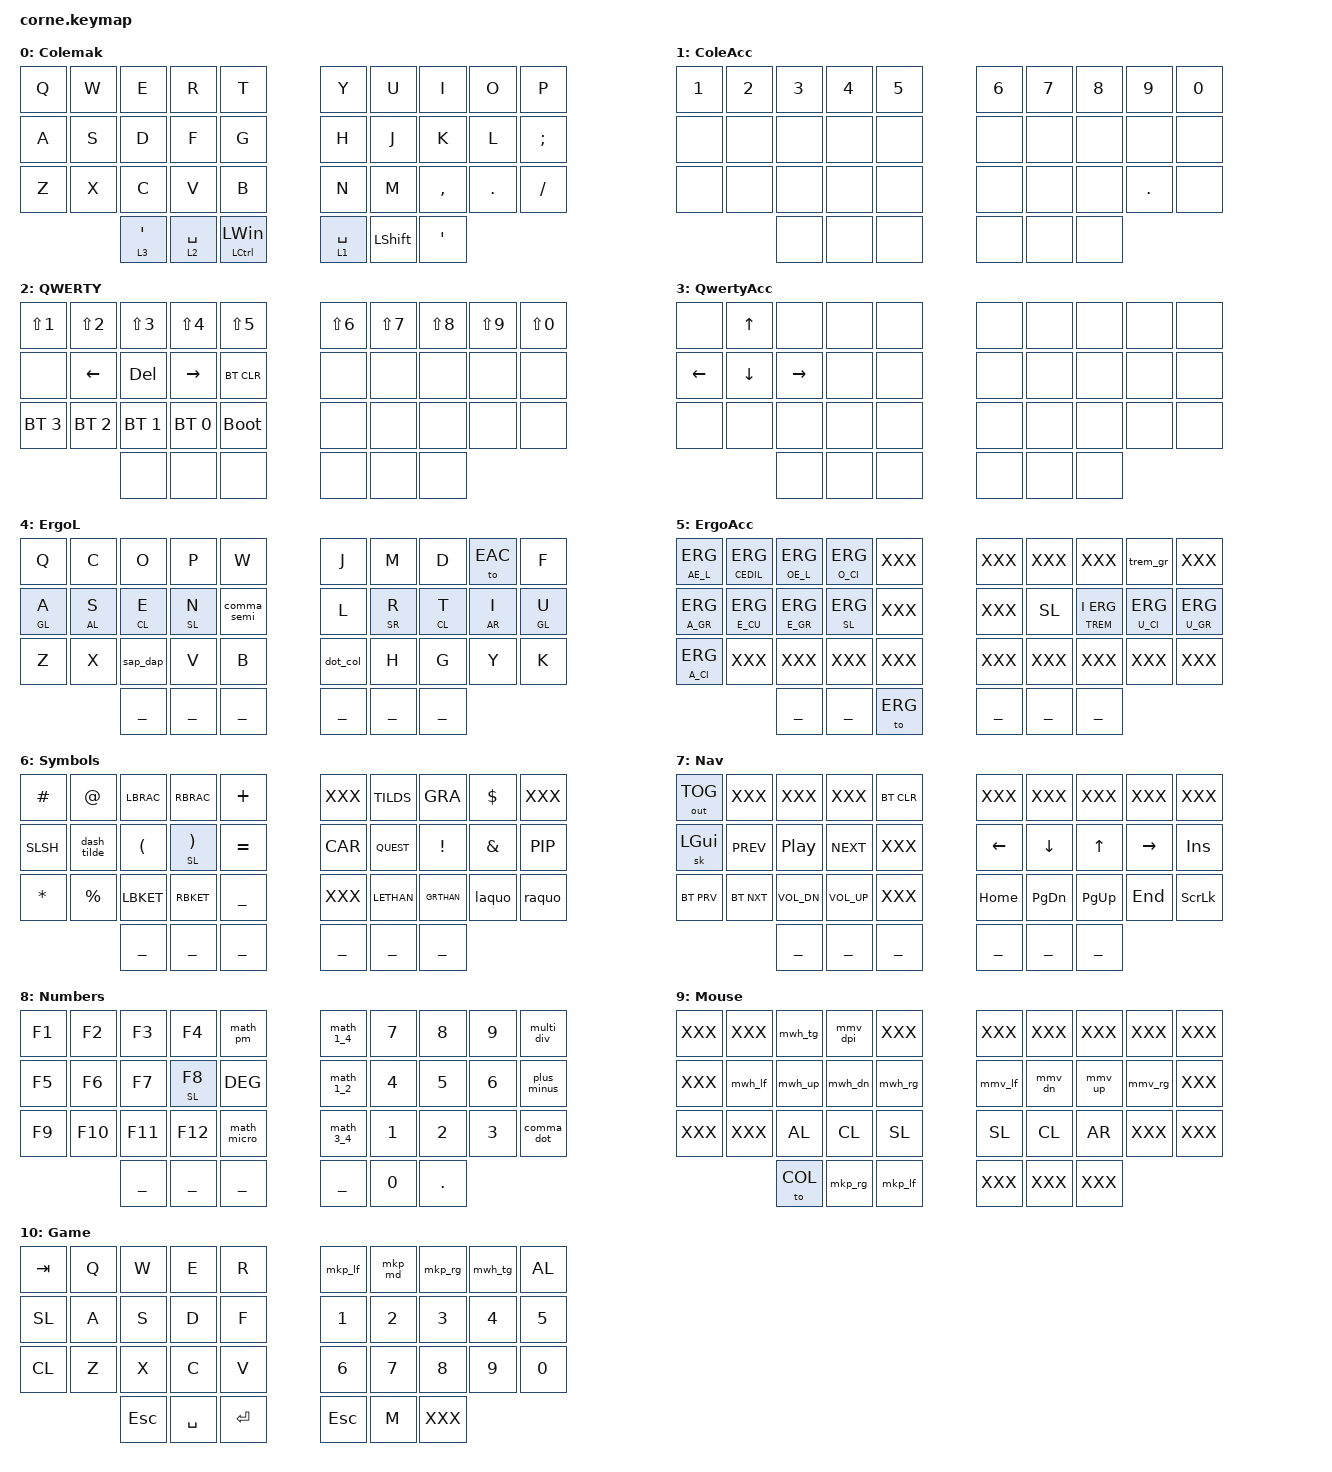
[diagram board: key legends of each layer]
#include <behaviors.dtsi>
#include <behaviors/mouse_keys.dtsi>
#include <dt-bindings/zmk/keys.h>
#include <dt-bindings/zmk/bt.h>
#include <dt-bindings/zmk/outputs.h>
#include <dt-bindings/zmk/mouse.h>

#include "constants.h"
#define HOST_OS LINUX // Needed for unicode international_chars

#include "zmk-helpers/helper.h"
#include "zmk-helpers/key-labels/36.h"
#include "../chars/french.dtsi"
#include "../chars/math.dtsi"
#include "../chars/typography.dtsi"
#include "../layouts/canadian-multilingual-standard.dtsi"
#include "../behaviors/combos_36.dtsi"
#include "../behaviors/hold-tap.dtsi"
#include "../behaviors/macros.dtsi"
#include "../behaviors/mod-morph.dtsi"
#include "../behaviors/mouse.dtsi"

ZMK_LAYER(Colemak,
// ╭───────────┬───────────┬───────────┬────────────┬────────────╮      ╭───────────┬─────────────┬─────────────┬────────────┬────────────╮
     &kp Q       &kp W       &kp E       &kp R        &kp T                &kp Y       &kp U         &kp I         &kp O        &kp P
// ├───────────┼───────────┼───────────┼────────────┼────────────┤      ├───────────┼─────────────┼─────────────┼────────────┼────────────┤
     &kp A       &kp S       &kp D       &kp F        &kp G                &kp H       &kp J         &kp K         &kp L        &kp SEMI
// ├───────────┼───────────┼───────────┼────────────┼────────────┤      ├───────────┼─────────────┼─────────────┼────────────┼────────────┤
     &kp Z       &kp X       &kp C       &kp V        &kp B                &kp N       &kp M         &kp COMMA     &kp DOT      &kp FSLH
// ╰───────────┴───────────┼───────────┼────────────┼────────────┤      ├───────────┼─────────────┼─────────────┼────────────┴────────────╯
                             &lt 3 SQT   &lt 2 SPACE &mt LCTRL LEFT_WIN  &lt 1 SPACE &kp LEFT_SHIFT  &kp SQT
//                         ╰───────────┴────────────┴────────────╯      ╰───────────┴─────────────┴─────────────╯
)

ZMK_LAYER(ColeAcc,
// ╭───────────┬───────────┬───────────┬────────────┬────────────╮ ╭───────────┬─────────────┬─────────────┬────────────┬────────────╮
      &kp N1       &kp N2      &kp N3      &kp N4       &kp N5        &kp N6       &kp N7        &kp N8        &kp N9       &kp N0 
// ├───────────┼───────────┼───────────┼────────────┼────────────┤ ├───────────┼─────────────┼─────────────┼────────────┼────────────┤
      &none        &none       &none       &none        &none         &none        &none         &none         &none        &none
// ├───────────┼───────────┼───────────┼────────────┼────────────┤ ├───────────┼─────────────┼─────────────┼────────────┼────────────┤
      &none        &none       &none       &none        &none         &none        &none         &none       &kp PERIOD     &none
// ╰───────────┴───────────┼───────────┼────────────┼────────────┤ ├───────────┼─────────────┼─────────────┼────────────┴────────────╯
                               &none       &none         &none         &none       &none         &none
//                         ╰───────────┴────────────┴────────────╯ ╰───────────┴─────────────┴─────────────╯
)

ZMK_LAYER(QWERTY,
// ╭───────────┬───────────┬───────────┬────────────┬────────────╮ ╭───────────┬─────────────┬─────────────┬────────────┬────────────╮
     &kp LS(N1)  &kp LS(N2)  &kp LS(N3)  &kp LS(N4)   &kp LS(N5)     &kp LS(N6)   &kp LS(N7)   &kp LS(N8)    &kp LS(N9)   &kp LS(N0)
// ├───────────┼───────────┼───────────┼────────────┼────────────┤ ├───────────┼─────────────┼─────────────┼────────────┼────────────┤
     &none    &kp LEFT_ARROW  &kp DEL    &kp RIGHT    &bt BT_CLR     &none        &none         &none          &none       &none
// ├───────────┼───────────┼───────────┼────────────┼────────────┤ ├───────────┼─────────────┼─────────────┼────────────┼────────────┤
   &bt BT_SEL 3 &bt BT_SEL 2 &bt BT_SEL 1 &bt BT_SEL 0 &bootloader    &none       &none         &none          &none       &none
// ╰───────────┴───────────┼───────────┼────────────┼────────────┤ ├───────────┼─────────────┼─────────────┼────────────┴────────────╯
                             &none         &none         &none         &none      &none         &none
//                         ╰───────────┴────────────┴────────────╯ ╰───────────┴─────────────┴─────────────╯
)

ZMK_LAYER(QwertyAcc,
// ╭───────────┬───────────┬───────────┬────────────┬────────────╮ ╭───────────┬─────────────┬─────────────┬────────────┬────────────╮
       &none    &kp UP_ARROW   &none        &none        &none          &none        &none         &none        &none       &none
// ├───────────┼───────────┼───────────┼────────────┼────────────┤ ├───────────┼─────────────┼─────────────┼────────────┼────────────┤
     &kp LEFT  &kp DOWN_ARROW &kp RIGHT     &none        &none          &none        &none         &none        &none       &none
// ├───────────┼───────────┼───────────┼────────────┼────────────┤ ├───────────┼─────────────┼─────────────┼────────────┼────────────┤
       &none       &none        &none       &none        &none          &none        &none         &none        &none       &none
// ╰───────────┴───────────┼───────────┼────────────┼────────────┤ ├───────────┼─────────────┼─────────────┼────────────┴────────────╯
                                &none       &none        &none          &none        &none         &none
//                         ╰───────────┴────────────┴────────────╯ ╰───────────┴─────────────┴─────────────╯
)

ZMK_LAYER(ErgoL,
// ╭───────────┬───────────┬───────────┬────────────┬────────────╮ ╭───────────┬─────────────┬─────────────┬────────────┬────────────╮
     &kp Q       &kp C       &kp O       &kp P        &kp W          &kp J       &kp M         &kp D         &to EAC      &kp F
// ├───────────┼───────────┼───────────┼────────────┼────────────┤ ├───────────┼─────────────┼─────────────┼────────────┼────────────┤
     &hml GL A   &hml AL S   &hml CL E   &hml SL N    &comma_semi    &kp L       &hmr SR R     &hmr CL T     &hmr AR I    &hmr GL U
// ├───────────┼───────────┼───────────┼────────────┼────────────┤ ├───────────┼─────────────┼─────────────┼────────────┼────────────┤
     &kp Z       &kp X       &sap_dap    &kp V        &kp B          &dot_col    &kp H         &kp G         &kp Y        &kp K
// ╰───────────┴───────────┼───────────┼────────────┼────────────┤ ├───────────┼─────────────┼─────────────┼────────────┴────────────╯
                             ___         ___          ___            ___         ___           ___
//                         ╰───────────┴────────────┴────────────╯ ╰───────────┴─────────────┴─────────────╯
)

ZMK_LAYER(ErgoAcc,
// ╭───────────┬───────────┬───────────┬────────────┬────────────╮ ╭───────────┬─────────────┬─────────────┬────────────┬────────────╮
     &AE_L ERG  &CEDIL ERG   &OE_L ERG   &O_CI ERG    XXX            XXX         XXX           XXX           &trem_gr     XXX
// ├───────────┼───────────┼───────────┼────────────┼────────────┤ ├───────────┼─────────────┼─────────────┼────────────┼────────────┤
     &A_GR ERG   &E_CU ERG   &E_GR ERG  &hrmec SL ERG XXX            XXX         &kp SL        &TREM I ERG   &U_CI ERG    &U_GR ERG
// ├───────────┼───────────┼───────────┼────────────┼────────────┤ ├───────────┼─────────────┼─────────────┼────────────┼────────────┤
     &A_CI ERG   XXX         XXX         XXX          XXX            XXX         XXX           XXX           XXX          XXX
// ╰───────────┴───────────┼───────────┼────────────┼────────────┤ ├───────────┼─────────────┼─────────────┼────────────┴────────────╯
                             ___         ___          &to ERG        ___         ___           ___
//                         ╰───────────┴────────────┴────────────╯ ╰───────────┴─────────────┴─────────────╯
)

ZMK_LAYER(Symbols,
// ╭───────────┬───────────┬───────────┬────────────┬────────────╮ ╭───────────┬─────────────┬─────────────┬────────────┬────────────╮
     &kp HASH    &kp AT      &kp LBRAC   &kp RBRAC    &kp PLUS       XXX         &kp TILDS     &GRA          &kp DLLR     XXX
// ├───────────┼───────────┼───────────┼────────────┼────────────┤ ├───────────┼─────────────┼─────────────┼────────────┼────────────┤
     &kp SLSH    &dash_tilde &kp LPAR   &hml SL RPAR  &kp EQUAL      &CAR        &kp QUEST     &kp EXCL      &kp AMPS     &kp PIP
// ├───────────┼───────────┼───────────┼────────────┼────────────┤ ├───────────┼─────────────┼─────────────┼────────────┼────────────┤
     &kp STAR    &kp PRCNT   &kp LBKET   &kp RBKET    &kp UNDER      XXX         &kp LETHAN    &kp GRTHAN    &laquo       &raquo
// ╰───────────┴───────────┼───────────┼────────────┼────────────┤ ├───────────┼─────────────┼─────────────┼────────────┴────────────╯
                             ___         ___          ___            ___         ___           ___
//                         ╰───────────┴────────────┴────────────╯ ╰───────────┴─────────────┴─────────────╯
)

ZMK_LAYER(Nav,
// ╭───────────┬───────────┬───────────┬────────────┬────────────╮ ╭───────────┬─────────────┬─────────────┬────────────┬────────────╮
    &out OUT_TOG XXX         XXX         XXX          &bt BT_CLR     XXX         XXX           XXX           XXX          XXX
// ├───────────┼───────────┼───────────┼────────────┼────────────┤ ├───────────┼─────────────┼─────────────┼────────────┼────────────┤
     &sk LGUI    &kp C_PREV  &kp C_PP    &kp C_NEXT   XXX            &kp LEFT    &kp DOWN      &kp UP        &kp RIGHT    &kp INS
// ├───────────┼───────────┼───────────┼────────────┼────────────┤ ├───────────┼─────────────┼─────────────┼────────────┼────────────┤
    &bt BT_PRV   &bt BT_NXT &kp C_VOL_DN &kp C_VOL_UP XXX            &kp HOME    &kp PG_DN     &kp PG_UP     &kp END      &kp SLCK
// ╰───────────┴───────────┼───────────┼────────────┼────────────┤ ├───────────┼─────────────┼─────────────┼────────────┴────────────╯
                             ___         ___          ___            ___         ___           ___
//                         ╰───────────┴────────────┴────────────╯ ╰───────────┴─────────────┴─────────────╯
)

ZMK_LAYER(Numbers,
// ╭───────────┬───────────┬───────────┬────────────┬────────────╮ ╭───────────┬─────────────┬─────────────┬────────────┬────────────╮
     &kp F1      &kp F2      &kp F3      &kp F4       &math_pm       &math_1_4   &kp N7        &kp N8        &kp N9       &multi_div
// ├───────────┼───────────┼───────────┼────────────┼────────────┤ ├───────────┼─────────────┼─────────────┼────────────┼────────────┤
     &kp F5      &kp F6      &kp F7      &hml SL F8   &kp DEG        &math_1_2   &kp N4        &kp N5        &kp N6       &plus_minus
// ├───────────┼───────────┼───────────┼────────────┼────────────┤ ├───────────┼─────────────┼─────────────┼────────────┼────────────┤
     &kp F9      &kp F10     &kp F11     &kp F12      &math_micro    &math_3_4   &kp N1        &kp N2        &kp N3       &comma_dot
// ╰───────────┴───────────┼───────────┼────────────┼────────────┤ ├───────────┼─────────────┼─────────────┼────────────┴────────────╯
                             ___         ___          ___            ___         &kp N0        &kp DOT
//                         ╰───────────┴────────────┴────────────╯ ╰───────────┴─────────────┴─────────────╯
)

ZMK_LAYER(Mouse,
// ╭───────────┬───────────┬───────────┬────────────┬────────────╮ ╭───────────┬─────────────┬─────────────┬────────────┬────────────╮
     XXX         XXX         &mwh_tg     &mmv_dpi     XXX            XXX         XXX           XXX           XXX          XXX
// ├───────────┼───────────┼───────────┼────────────┼────────────┤ ├───────────┼─────────────┼─────────────┼────────────┼────────────┤
     XXX         &mwh_lf     &mwh_up     &mwh_dn      &mwh_rg        &mmv_lf     &mmv_dn       &mmv_up       &mmv_rg      XXX
// ├───────────┼───────────┼───────────┼────────────┼────────────┤ ├───────────┼─────────────┼─────────────┼────────────┼────────────┤
     XXX         XXX         &kp AL      &kp CL       &kp SL         &kp SL      &kp CL        &kp AR        XXX          XXX
// ╰───────────┴───────────┼───────────┼────────────┼────────────┤ ├───────────┼─────────────┼─────────────┼────────────┴────────────╯
                             &to COL     &mkp_rg      &mkp_lf        XXX         XXX           XXX
//                         ╰───────────┴────────────┴────────────╯ ╰───────────┴─────────────┴─────────────╯
)

ZMK_LAYER(Game,
// ╭───────────┬───────────┬───────────┬────────────┬────────────╮ ╭───────────┬─────────────┬─────────────┬────────────┬────────────╮
     &kp TAB     &kp Q       &kp W       &kp E        &kp R          &mkp_lf     &mkp_md       &mkp_rg       &mwh_tg      &kp AL
// ├───────────┼───────────┼───────────┼────────────┼────────────┤ ├───────────┼─────────────┼─────────────┼────────────┼────────────┤
     &kp SL      &kp A       &kp S       &kp D        &kp F          &kp N1      &kp N2        &kp N3        &kp N4       &kp N5
// ├───────────┼───────────┼───────────┼────────────┼────────────┤ ├───────────┼─────────────┼─────────────┼────────────┼────────────┤
     &kp CL      &kp Z       &kp X       &kp C        &kp V          &kp N6      &kp N7        &kp N8        &kp N9       &kp N0
// ╰───────────┴───────────┼───────────┼────────────┼────────────┤ ├───────────┼─────────────┼─────────────┼────────────┴────────────╯
                             &kp ESC     &kp SPACE    &kp RET        &kp ESC     &kp M         XXX
//                         ╰───────────┴────────────┴────────────╯ ╰───────────┴─────────────┴─────────────╯
)

ZMK_APPLY_MATRIX_TRANSFORM(five_column_transform)
